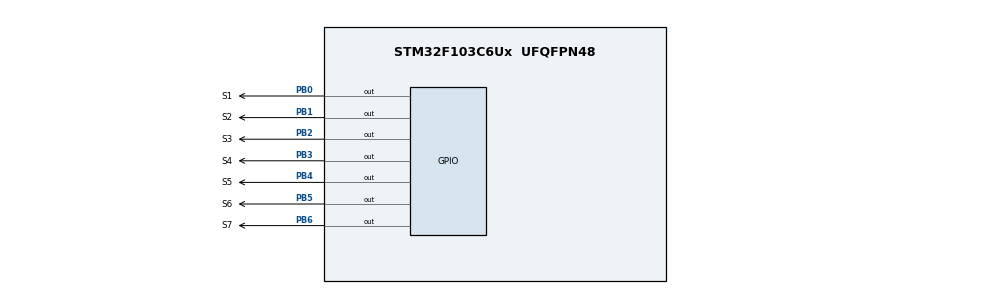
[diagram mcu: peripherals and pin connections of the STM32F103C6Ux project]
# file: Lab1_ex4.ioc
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Mcu.Family=STM32F1
Mcu.Name=STM32F103C6Ux
Mcu.Package=UFQFPN48
NVIC.PriorityGroup=NVIC_PRIORITYGROUP_4
PB0.GPIO_Label=S1
PB0.Signal=GPIO_Output
PB1.GPIO_Label=S2
PB1.Signal=GPIO_Output
PB2.GPIO_Label=S3
PB2.Signal=GPIO_Output
PB3.GPIO_Label=S4
PB3.Signal=GPIO_Output
PB4.GPIO_Label=S5
PB4.Signal=GPIO_Output
PB5.GPIO_Label=S6
PB5.Signal=GPIO_Output
PB6.GPIO_Label=S7
PB6.Signal=GPIO_Output
ProjectManager.HeapSize=0x200
ProjectManager.StackSize=0x400
ProjectManager.TargetToolchain=STM32CubeIDE
RCC.APB1Freq_Value=8000000
RCC.APB2Freq_Value=8000000
VP_SYS_VS_ND.Mode=No_Debug
board=custom

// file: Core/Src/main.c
/* USER CODE BEGIN Header */
/**
  ******************************************************************************
  * @file           : main.c
  * @brief          : Main program body
  ******************************************************************************
  * @attention
  *
  * <h2><center>&copy; Copyright (c) 2023 STMicroelectronics.
  * All rights reserved.</center></h2>
  *
  * This software component is licensed by ST under BSD 3-Clause license,
  * the "License"; You may not use this file except in compliance with the
  * License. You may obtain a copy of the License at:
  *                        opensource.org/licenses/BSD-3-Clause
  *
  ******************************************************************************
  */
/* USER CODE END Header */
#include "main.h"

void SystemClock_Config(void);
static void MX_GPIO_Init(void);

void display7SEG(int num) {
	if(num == 0) {
		HAL_GPIO_WritePin(S1_GPIO_Port, S1_Pin, 0);
		HAL_GPIO_WritePin(S2_GPIO_Port, S2_Pin, 0);
		HAL_GPIO_WritePin(S3_GPIO_Port, S3_Pin, 0);
		HAL_GPIO_WritePin(S4_GPIO_Port, S4_Pin, 0);
		HAL_GPIO_WritePin(S5_GPIO_Port, S5_Pin, 0);
		HAL_GPIO_WritePin(S6_GPIO_Port, S6_Pin, 0);
		HAL_GPIO_WritePin(S7_GPIO_Port, S7_Pin, 1);
	}
	else if(num == 1) {

	}
	switch(num) {
		case 0:
			HAL_GPIO_WritePin(S1_GPIO_Port, S1_Pin, 0);
			HAL_GPIO_WritePin(S2_GPIO_Port, S2_Pin, 0);
			HAL_GPIO_WritePin(S3_GPIO_Port, S3_Pin, 0);
			HAL_GPIO_WritePin(S4_GPIO_Port, S4_Pin, 0);
			HAL_GPIO_WritePin(S5_GPIO_Port, S5_Pin, 0);
			HAL_GPIO_WritePin(S6_GPIO_Port, S6_Pin, 0);
			HAL_GPIO_WritePin(S7_GPIO_Port, S7_Pin, 1);
			break;
		case 1:
			HAL_GPIO_WritePin(S1_GPIO_Port, S1_Pin, 1);
			HAL_GPIO_WritePin(S2_GPIO_Port, S2_Pin, 0);
			HAL_GPIO_WritePin(S3_GPIO_Port, S3_Pin, 0);
			HAL_GPIO_WritePin(S4_GPIO_Port, S4_Pin, 1);
			HAL_GPIO_WritePin(S5_GPIO_Port, S5_Pin, 1);
			HAL_GPIO_WritePin(S6_GPIO_Port, S6_Pin, 1);
			HAL_GPIO_WritePin(S7_GPIO_Port, S7_Pin, 1);
			break;
		case 2:
			HAL_GPIO_WritePin(S1_GPIO_Port, S1_Pin, 0);
			HAL_GPIO_WritePin(S2_GPIO_Port, S2_Pin, 0);
			HAL_GPIO_WritePin(S3_GPIO_Port, S3_Pin, 1);
			HAL_GPIO_WritePin(S4_GPIO_Port, S4_Pin, 0);
			HAL_GPIO_WritePin(S5_GPIO_Port, S5_Pin, 0);
			HAL_GPIO_WritePin(S6_GPIO_Port, S6_Pin, 1);
			HAL_GPIO_WritePin(S7_GPIO_Port, S7_Pin, 0);
			break;
		case 3:
			HAL_GPIO_WritePin(S1_GPIO_Port, S1_Pin, 0);
			HAL_GPIO_WritePin(S2_GPIO_Port, S2_Pin, 0);
			HAL_GPIO_WritePin(S3_GPIO_Port, S3_Pin, 0);
			HAL_GPIO_WritePin(S4_GPIO_Port, S4_Pin, 0);
			HAL_GPIO_WritePin(S5_GPIO_Port, S5_Pin, 1);
			HAL_GPIO_WritePin(S6_GPIO_Port, S6_Pin, 1);
			HAL_GPIO_WritePin(S7_GPIO_Port, S7_Pin, 0);
			break;
		case 4:
			HAL_GPIO_WritePin(S1_GPIO_Port, S1_Pin, 1);
			HAL_GPIO_WritePin(S2_GPIO_Port, S2_Pin, 0);
			HAL_GPIO_WritePin(S3_GPIO_Port, S3_Pin, 0);
			HAL_GPIO_WritePin(S4_GPIO_Port, S4_Pin, 1);
			HAL_GPIO_WritePin(S5_GPIO_Port, S5_Pin, 1);
			HAL_GPIO_WritePin(S6_GPIO_Port, S6_Pin, 0);
			HAL_GPIO_WritePin(S7_GPIO_Port, S7_Pin, 0);
			break;
		case 5:
			HAL_GPIO_WritePin(S1_GPIO_Port, S1_Pin, 0);
			HAL_GPIO_WritePin(S2_GPIO_Port, S2_Pin, 1);
			HAL_GPIO_WritePin(S3_GPIO_Port, S3_Pin, 0);
			HAL_GPIO_WritePin(S4_GPIO_Port, S4_Pin, 0);
			HAL_GPIO_WritePin(S5_GPIO_Port, S5_Pin, 1);
			HAL_GPIO_WritePin(S6_GPIO_Port, S6_Pin, 0);
			HAL_GPIO_WritePin(S7_GPIO_Port, S7_Pin, 0);
			break;
		case 6:
			HAL_GPIO_WritePin(S1_GPIO_Port, S1_Pin, 0);
			HAL_GPIO_WritePin(S2_GPIO_Port, S2_Pin, 1);
			HAL_GPIO_WritePin(S3_GPIO_Port, S3_Pin, 0);
			HAL_GPIO_WritePin(S4_GPIO_Port, S4_Pin, 0);
			HAL_GPIO_WritePin(S5_GPIO_Port, S5_Pin, 0);
			HAL_GPIO_WritePin(S6_GPIO_Port, S6_Pin, 0);
			HAL_GPIO_WritePin(S7_GPIO_Port, S7_Pin, 0);
			break;
		case 7:
			HAL_GPIO_WritePin(S1_GPIO_Port, S1_Pin, 0);
			HAL_GPIO_WritePin(S2_GPIO_Port, S2_Pin, 0);
			HAL_GPIO_WritePin(S3_GPIO_Port, S3_Pin, 0);
			HAL_GPIO_WritePin(S4_GPIO_Port, S4_Pin, 1);
			HAL_GPIO_WritePin(S5_GPIO_Port, S5_Pin, 1);
			HAL_GPIO_WritePin(S6_GPIO_Port, S6_Pin, 1);
			HAL_GPIO_WritePin(S7_GPIO_Port, S7_Pin, 1);
			break;
		case 8:
			HAL_GPIO_WritePin(S1_GPIO_Port, S1_Pin, 0);
			HAL_GPIO_WritePin(S2_GPIO_Port, S2_Pin, 0);
			HAL_GPIO_WritePin(S3_GPIO_Port, S3_Pin, 0);
			HAL_GPIO_WritePin(S4_GPIO_Port, S4_Pin, 0);
			HAL_GPIO_WritePin(S5_GPIO_Port, S5_Pin, 0);
			HAL_GPIO_WritePin(S6_GPIO_Port, S6_Pin, 0);
			HAL_GPIO_WritePin(S7_GPIO_Port, S7_Pin, 0);
			break;
		case 9:
			HAL_GPIO_WritePin(S1_GPIO_Port, S1_Pin, 0);
			HAL_GPIO_WritePin(S2_GPIO_Port, S2_Pin, 0);
			HAL_GPIO_WritePin(S3_GPIO_Port, S3_Pin, 0);
			HAL_GPIO_WritePin(S4_GPIO_Port, S4_Pin, 0);
			HAL_GPIO_WritePin(S5_GPIO_Port, S5_Pin, 1);
			HAL_GPIO_WritePin(S6_GPIO_Port, S6_Pin, 0);
			HAL_GPIO_WritePin(S7_GPIO_Port, S7_Pin, 0);
			break;
		default:
			HAL_GPIO_WritePin(S1_GPIO_Port, S1_Pin, 0);
			HAL_GPIO_WritePin(S2_GPIO_Port, S2_Pin, 0);
			HAL_GPIO_WritePin(S3_GPIO_Port, S3_Pin, 0);
			HAL_GPIO_WritePin(S4_GPIO_Port, S4_Pin, 0);
			HAL_GPIO_WritePin(S5_GPIO_Port, S5_Pin, 0);
			HAL_GPIO_WritePin(S6_GPIO_Port, S6_Pin, 0);
			HAL_GPIO_WritePin(S7_GPIO_Port, S7_Pin, 0);
			break;

	}

}
int main(void)
{

  /* MCU Configuration--------------------------------------------------------*/

  /* Reset of all peripherals, Initializes the Flash interface and the Systick. */
  HAL_Init();

  /* Configure the system clock */
  SystemClock_Config();

  /* Initialize all configured peripherals */
  MX_GPIO_Init();

  int i = 0;
  /* Infinite loop */
  /* USER CODE BEGIN WHILE */
  while (1)
  {
	  if(i >= 10) i = 0;
	  display7SEG(i++) ;
	  HAL_Delay(1000) ;
    /* USER CODE END WHILE */

  }
}

void SystemClock_Config(void)
{
  RCC_OscInitTypeDef RCC_OscInitStruct = {0};
  RCC_ClkInitTypeDef RCC_ClkInitStruct = {0};

  /** Initializes the RCC Oscillators according to the specified parameters
  * in the RCC_OscInitTypeDef structure.
  */
  RCC_OscInitStruct.OscillatorType = RCC_OSCILLATORTYPE_HSI;
  RCC_OscInitStruct.HSIState = RCC_HSI_ON;
  RCC_OscInitStruct.HSICalibrationValue = RCC_HSICALIBRATION_DEFAULT;
  RCC_OscInitStruct.PLL.PLLState = RCC_PLL_NONE;
  if (HAL_RCC_OscConfig(&RCC_OscInitStruct) != HAL_OK)
  {
    Error_Handler();
  }
  /** Initializes the CPU, AHB and APB buses clocks
  */
  RCC_ClkInitStruct.ClockType = RCC_CLOCKTYPE_HCLK|RCC_CLOCKTYPE_SYSCLK
                              |RCC_CLOCKTYPE_PCLK1|RCC_CLOCKTYPE_PCLK2;
  RCC_ClkInitStruct.SYSCLKSource = RCC_SYSCLKSOURCE_HSI;
  RCC_ClkInitStruct.AHBCLKDivider = RCC_SYSCLK_DIV1;
  RCC_ClkInitStruct.APB1CLKDivider = RCC_HCLK_DIV1;
  RCC_ClkInitStruct.APB2CLKDivider = RCC_HCLK_DIV1;

  if (HAL_RCC_ClockConfig(&RCC_ClkInitStruct, FLASH_LATENCY_0) != HAL_OK)
  {
    Error_Handler();
  }
}

static void MX_GPIO_Init(void)
{
  GPIO_InitTypeDef GPIO_InitStruct = {0};

  /* GPIO Ports Clock Enable */
  __HAL_RCC_GPIOB_CLK_ENABLE();

  /*Configure GPIO pin Output Level */
  HAL_GPIO_WritePin(GPIOB, S1_Pin|S2_Pin|S3_Pin|S4_Pin
                          |S5_Pin|S6_Pin|S7_Pin, GPIO_PIN_RESET);

  /*Configure GPIO pins : S1_Pin S2_Pin S3_Pin S4_Pin
                           S5_Pin S6_Pin S7_Pin */
  GPIO_InitStruct.Pin = S1_Pin|S2_Pin|S3_Pin|S4_Pin
                          |S5_Pin|S6_Pin|S7_Pin;
  GPIO_InitStruct.Mode = GPIO_MODE_OUTPUT_PP;
  GPIO_InitStruct.Pull = GPIO_NOPULL;
  GPIO_InitStruct.Speed = GPIO_SPEED_FREQ_LOW;
  HAL_GPIO_Init(GPIOB, &GPIO_InitStruct);

}

void Error_Handler(void)
{
  __disable_irq();
  while (1)
  {
  }
}

/************************ (C) COPYRIGHT STMicroelectronics *****END OF FILE****/
